AUTOSAR XML (schema 4-2-1)
package /ComponentTypes
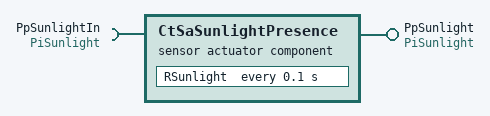
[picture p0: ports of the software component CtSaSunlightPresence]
  sensor actuator sw component type CtSaSunlightPresence
    provide port PpSunlight: nonqueued-sender-com-spec{data-element=DeSunlight, init-value=constant-reference=CSunlight}, provided-interface=PiSunlight
    require port PpSunlightIn: nonqueued-receiver-com-spec{data-element=DeSunlight, filter=data-filter-type=ALWAYS, init-value=constant-reference=CSunlight}, required-interface=PiSunlight
    behavior CtSaSunlightPresence_InternalBehavior: data-type-mapping=ApMappingSet
      timing event TMT_RSunlight: start-on-event=RSunlight, period=0.1
      runnable RSunlight
        data-receive-point-by-arguments:
          access REC_PpSunlightIn_DeSunlight: accessed-variable=PpSunlightIn.DeSunlight
        data-send-points:
          access SEND_PpSunlight_DeSunlight: accessed-variable=PpSunlight.DeSunlight
  swc implementation CtSaSunlightPresence_Implementation: behavior=CtSaSunlightPresence_InternalBehavior
    code-descriptors:
      code Default: artifact-descriptors=autosar-engineering-object={short-label=Default, category=SWSRC}
